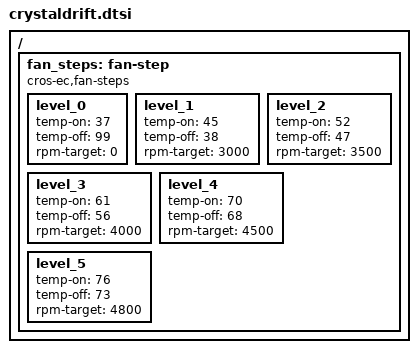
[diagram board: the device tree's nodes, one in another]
/* Copyright 2022 The ChromiumOS Authors
 * Use of this source code is governed by a BSD-style license that can be
 * found in the LICENSE file.
 */

#include <board-overlays/native_sim.dts>
#include <cros/binman.dtsi>
#include <cros/thermistor/thermistor.dtsi>
#include <dt-bindings/gpio_defines.h>
#include <dt-bindings/pwm/pwm.h>
#include <dt-bindings/wake_mask_event_defines.h>
#include <freq.h>

#include "../native_sim.overlay"

/ {
	fan_steps: fan-step {
		compatible = "cros-ec,fan-steps";
		level_0 {
			temp-on = <37>;
			temp-off = <99>;
			rpm-target = <0>;
		};
		level_1 {
			temp-on = <45>;
			temp-off = <38>;
			rpm-target = <3000>;
		};
		level_2 {
			temp-on = <52>;
			temp-off = <47>;
			rpm-target = <3500>;
		};
		level_3 {
			temp-on = <61>;
			temp-off = <56>;
			rpm-target = <4000>;
		};
		level_4 {
			temp-on = <70>;
			temp-off = <68>;
			rpm-target = <4500>;
		};
		level_5 {
			temp-on = <76>;
			temp-off = <73>;
			rpm-target = <4800>;
		};
	};
};
